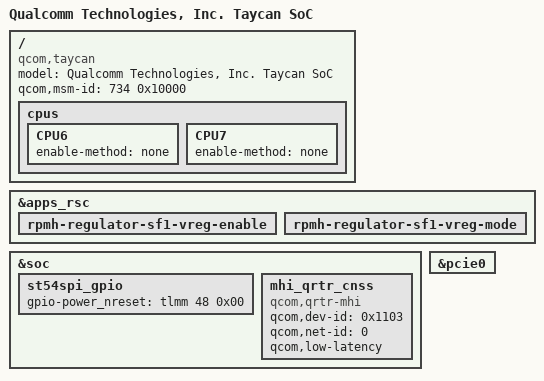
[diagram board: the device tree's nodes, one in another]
// SPDX-License-Identifier: BSD-3-Clause
/*
 * Copyright (c) Qualcomm Technologies, Inc. and/or its subsidiaries.
 */

#include "ravelin.dtsi"

/ {
	model = "Qualcomm Technologies, Inc. Taycan SoC";
	compatible = "qcom,taycan";
	qcom,msm-id = <734 0x10000>;

	cpus {
		CPU6 {
			enable-method = "none";
		};

		CPU7 {
			enable-method = "none";
		};
	};
};

&apps_rsc {
	rpmh-regulator-sf1-vreg-enable {
		status = "ok";
	};

	rpmh-regulator-sf1-vreg-mode {
		status = "ok";
	};
};

&soc {
	st54spi_gpio {
		status = "ok";
		/* gpio used as SE_nRESET */
		gpio-power_nreset = <&tlmm 48 0x00>;
	};

	mhi_qrtr_cnss {
		compatible = "qcom,qrtr-mhi";
		qcom,dev-id = <0x1103>;
		qcom,net-id = <0>;
		qcom,low-latency;
	};
};

&pcie0 {
/delete-property/ qcom,config-recovery;
/delete-property/ qcom,drv-supported;
};
